AUTOSAR XML (schema 4-0-3)
standard types defined: Boolean, UInt16, UInt32, UInt8
package /AUTOSAR_Platform/DataConstrs
  range DC_Boolean: raw 0..1
  range DC_UInt16: raw 0..65535
  range DC_UInt8: raw 0..255
package /PATAC/MSM/ComponentTypes
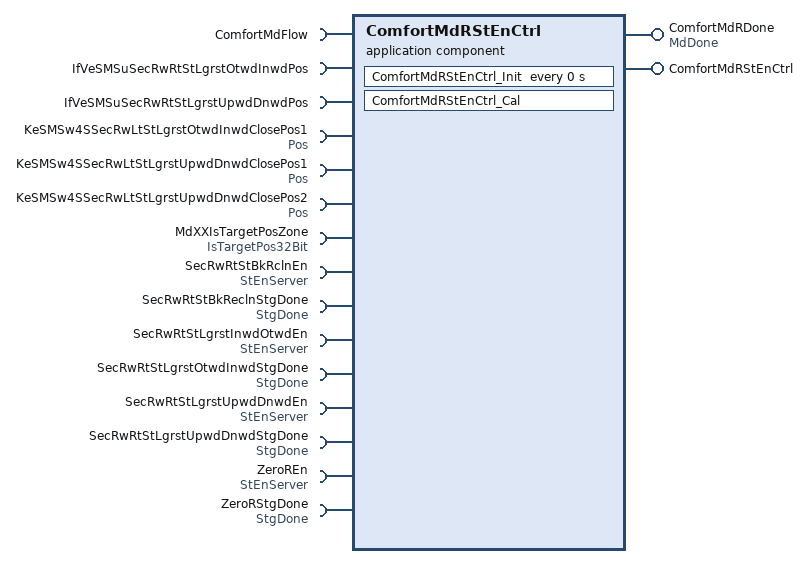
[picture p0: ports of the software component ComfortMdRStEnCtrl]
  application sw component type ComfortMdRStEnCtrl
    provide port ComfortMdRDone: nonqueued-sender-com-spec{data-element=MdDone/Val, init-value=0}, provided-interface=MdDone
    provide port ComfortMdRStEnCtrl: server-com-spec{operation=ComfortMdRStEnCtrl/Cal, queue-length=1}, provided-interface=ComfortMdRStEnCtrl
    15 x require port:
      ComfortMdFlow: client-com-spec=ComfortMdFlow/Cal, required-interface=ComfortMdFlow
      IfVeSMSuSecRwRtStLgrstOtwdInwdPos: nonqueued-receiver-com-spec{data-element=IfVeSMSuSecRwRtStLgrstOtwdInwdPos/Val, filter=data-filter-type=ALWAYS, init-value=0}, required-interface=IfVeSMSuSecRwRtStLgrstOtwdInwdPos
      IfVeSMSuSecRwRtStLgrstUpwdDnwdPos: nonqueued-receiver-com-spec{data-element=IfVeSMSuSecRwRtStLgrstUpwdDnwdPos/Val, filter=data-filter-type=ALWAYS, init-value=0}, required-interface=IfVeSMSuSecRwRtStLgrstUpwdDnwdPos
      KeSMSw4SSecRwLtStLgrstOtwdInwdClosePos1: parameter-require-com-spec{init-value=0, parameter=Val}, required-interface=Pos
      KeSMSw4SSecRwLtStLgrstUpwdDnwdClosePos1: parameter-require-com-spec{init-value=0, parameter=Val}, required-interface=Pos
      KeSMSw4SSecRwLtStLgrstUpwdDnwdClosePos2: parameter-require-com-spec{init-value=0, parameter=Val}, required-interface=Pos
      MdXXIsTargetPosZone: nonqueued-receiver-com-spec{data-element=IsTargetPos32Bit/Val, filter=data-filter-type=ALWAYS, init-value=0}, required-interface=IsTargetPos32Bit
      SecRwRtStBkRclnEn: required-com-specs=[Clear, Get, Set], required-interface=StEnServer
      SecRwRtStBkReclnStgDone: nonqueued-receiver-com-spec{data-element=StgDone/Val, filter=data-filter-type=ALWAYS, init-value=0}, required-interface=StgDone
      SecRwRtStLgrstInwdOtwdEn: required-com-specs=[Clear, Get, Set], required-interface=StEnServer
      SecRwRtStLgrstOtwdInwdStgDone: nonqueued-receiver-com-spec{data-element=StgDone/Val, filter=data-filter-type=ALWAYS, init-value=0}, required-interface=StgDone
      SecRwRtStLgrstUpwdDnwdEn: required-com-specs=[Clear, Get, Set], required-interface=StEnServer
      SecRwRtStLgrstUpwdDnwdStgDone: nonqueued-receiver-com-spec{data-element=StgDone/Val, filter=data-filter-type=ALWAYS, init-value=0}, required-interface=StgDone
      ZeroREn: required-com-specs=[Clear, Get, Set], required-interface=StEnServer
      ZeroRStgDone: nonqueued-receiver-com-spec{data-element=StgDone/Val, filter=data-filter-type=ALWAYS, init-value=0}, required-interface=StgDone
    behavior ComfortMdRStEnCtrl_InternalBehavior
      operation invoked event OIT_ComfortMdRStEnCtrl_Cal_ComfortMdRStEnCtrl_Cal: start-on-event=ComfortMdRStEnCtrl_Cal, operation=ComfortMdRStEnCtrl.Cal
      timing event ComfortMdRStEnCtrl_InitEvent: start-on-event=ComfortMdRStEnCtrl_Init, period=0
      runnable ComfortMdRStEnCtrl_Cal
        data-receive-point-by-arguments:
          7 x access:
            REC_IfVeSMSuSecRwRtStLgrstOtwdInwdPos_Val: accessed-variable=IfVeSMSuSecRwRtStLgrstOtwdInwdPos.Val
            REC_IfVeSMSuSecRwRtStLgrstUpwdDnwdPos_Val: accessed-variable=IfVeSMSuSecRwRtStLgrstUpwdDnwdPos.Val
            REC_MdXXIsTargetPosZone_Val: accessed-variable=MdXXIsTargetPosZone.Val
            REC_SecRwRtStBkReclnStgDone_Val: accessed-variable=SecRwRtStBkReclnStgDone.Val
            REC_SecRwRtStLgrstOtwdInwdStgDone_Val: accessed-variable=SecRwRtStLgrstOtwdInwdStgDone.Val
            REC_SecRwRtStLgrstUpwdDnwdStgDone_Val: accessed-variable=SecRwRtStLgrstUpwdDnwdStgDone.Val
            REC_ZeroRStgDone_Val: accessed-variable=ZeroRStgDone.Val
        data-send-points:
          access SEND_ComfortMdRDone_Val: accessed-variable=ComfortMdRDone.Val
        parameter access PA_KeSMSw4SSecRwLtStLgrstOtwdInwdClosePos1_Val: accessed-parameter=KeSMSw4SSecRwLtStLgrstOtwdInwdClosePos1.Val
        parameter access PA_KeSMSw4SSecRwLtStLgrstUpwdDnwdClosePos1_Val: accessed-parameter=KeSMSw4SSecRwLtStLgrstUpwdDnwdClosePos1.Val
        parameter access PA_KeSMSw4SSecRwLtStLgrstUpwdDnwdClosePos2_Val: accessed-parameter=KeSMSw4SSecRwLtStLgrstUpwdDnwdClosePos2.Val
        9 x sync call, all with timeout=0:
          SC_ComfortMdFlow_Cal: operation=ComfortMdFlow.Cal
          SC_SecRwRtStBkRclnEn_Clear: operation=SecRwRtStBkRclnEn.Clear
          SC_SecRwRtStBkRclnEn_Set: operation=SecRwRtStBkRclnEn.Set
          SC_SecRwRtStLgrstInwdOtwdEn_Clear: operation=SecRwRtStLgrstInwdOtwdEn.Clear
          SC_SecRwRtStLgrstInwdOtwdEn_Set: operation=SecRwRtStLgrstInwdOtwdEn.Set
          SC_SecRwRtStLgrstUpwdDnwdEn_Clear: operation=SecRwRtStLgrstUpwdDnwdEn.Clear
          SC_SecRwRtStLgrstUpwdDnwdEn_Set: operation=SecRwRtStLgrstUpwdDnwdEn.Set
          SC_ZeroREn_Clear: operation=ZeroREn.Clear
          SC_ZeroREn_Set: operation=ZeroREn.Set
      runnable ComfortMdRStEnCtrl_Init
        parameter access PA_KeSMSw4SSecRwLtStLgrstOtwdInwdClosePos1_Val: accessed-parameter=KeSMSw4SSecRwLtStLgrstOtwdInwdClosePos1.Val
        parameter access PA_KeSMSw4SSecRwLtStLgrstUpwdDnwdClosePos1_Val: accessed-parameter=KeSMSw4SSecRwLtStLgrstUpwdDnwdClosePos1.Val
        parameter access PA_KeSMSw4SSecRwLtStLgrstUpwdDnwdClosePos2_Val: accessed-parameter=KeSMSw4SSecRwLtStLgrstUpwdDnwdClosePos2.Val
  swc implementation ComfortMdRStEnCtrl_Implementation: behavior=ComfortMdRStEnCtrl_InternalBehavior
    code-descriptors:
      code Default: artifact-descriptors=autosar-engineering-object={short-label=Default, category=SWSRC}
package /PATAC/MSM/ModeAdjust/CalPortInterface
  parameter interface Pos
    parameter data prototype Val: sw-calibration-access=READ-WRITE, type=UInt16
package /PATAC/MSM/ModeAdjust/PortInterface
  client server interface ComfortMdFlow
    operation Cal
      14 x arg, all with server-argument-impl-policy=USE-ARGUMENT-TYPE:
        LgrstUpwdDnwdPos: type=UInt16, direction=IN
        LgrstUpwdDnwdClosePos1: type=UInt16, direction=IN
        LgrstUpwdStgDone: type=Implementation/Boolean, direction=IN
        ZeroStgDone: type=Implementation/Boolean, direction=IN
        LgrstInwdStgDone: type=Implementation/Boolean, direction=IN
        Failflg: type=Implementation/Boolean, direction=OUT
        LgrstInwdOtwdEn: type=Implementation/Boolean, direction=OUT
        LgrstUpwdDnwdEn: type=Implementation/Boolean, direction=OUT
        ZeroEn: type=Implementation/Boolean, direction=OUT
        BkReclnStgDone: type=DataTypes/Boolean, direction=IN
        BkReclnEn: type=DataTypes/Boolean, direction=OUT
        LgrstUpwdDnwdClosePos2: type=UInt16, direction=IN
        LgrstInwdOtwdClosePos1: type=UInt16, direction=IN
        LgrstInwdOtwdPos: type=UInt16, direction=IN
  client server interface ComfortMdRStEnCtrl
    operation Cal
  client server interface StEnServer
    operation Clear
      arg data: type=UInt8, direction=IN, server-argument-impl-policy=USE-ARGUMENT-TYPE
    operation Get
      arg data: type=UInt32, direction=OUT, server-argument-impl-policy=USE-ARGUMENT-TYPE
    operation Set
      arg data: type=UInt8, direction=IN, server-argument-impl-policy=USE-ARGUMENT-TYPE
  sender receiver interface IsTargetPos32Bit: invalidation-policy{data-element=IsTargetPos32Bit/Val, handle-invalid=DONT-INVALIDATE}
    data Val: type=UInt32
  sender receiver interface MdDone: invalidation-policy{data-element=MdDone/Val, handle-invalid=DONT-INVALIDATE}
    data Val: type=UInt8
  sender receiver interface StgDone: invalidation-policy{data-element=StgDone/Val, handle-invalid=DONT-INVALIDATE}
    data Val: type=Implementation/Boolean
package /PATAC/MSM/PortInterfaces
  sender receiver interface IfVeSMSuSecRwRtStLgrstOtwdInwdPos: invalidation-policy{data-element=IfVeSMSuSecRwRtStLgrstOtwdInwdPos/Val, handle-invalid=DONT-INVALIDATE}
    data Val: type=UInt16
  sender receiver interface IfVeSMSuSecRwRtStLgrstUpwdDnwdPos: invalidation-policy{data-element=IfVeSMSuSecRwRtStLgrstUpwdDnwdPos/Val, handle-invalid=DONT-INVALIDATE}
    data Val: type=UInt16
